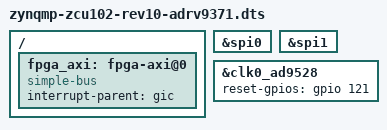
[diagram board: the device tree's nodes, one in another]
#include "zynqmp-zcu102-rev1.0.dts"

//&i2c1 {
//	i2cswitch@75 {
//		i2c@0 {
//			#address-cells = <1>;
//			#size-cells = <0>;
//			reg = <0>;
//			/* HPC0_IIC */
//			ad7291@2f {
//				compatible = "adi,ad7291";
//				reg = <0x2f>;
//			};
//
//			eeprom@50 {
//				compatible = "at24,24c02";
//				reg = <0x50>;
//			};
//
//		};
//	};
//};

/ {
	fpga_axi: fpga-axi@0 {
		interrupt-parent = <&gic>;
		compatible = "simple-bus";
		#address-cells = <0x2>;
		#size-cells = <0x1>;
		ranges = <0 0 0 0 0xffffffff>;

	};
};

&spi0 {
	status = "okay";
};

&spi1 {
	status = "okay";
};

#define fmc_spi spi0

#include "adi-adrv9371.dtsi"

// ad9371_dac_fifo_bypass_s 60
// ad9528_reset_b,       // 59
// ad9528_sysref_req,    // 58
// ad9371_tx1_enable,    // 57
// ad9371_tx2_enable,    // 56
// ad9371_rx1_enable,    // 55
// ad9371_rx2_enable,    // 54
// ad9371_test,          // 53
// ad9371_reset_b,       // 52
// ad9371_gpint,         // 51
// ad9371_gpio_00,       // 50
// ad9371_gpio_01,       // 49
// ad9371_gpio_02,       // 48
// ad9371_gpio_03,       // 47
// ad9371_gpio_04,       // 46
// ad9371_gpio_05,       // 45
// ad9371_gpio_06,       // 44
// ad9371_gpio_07,       // 43
// ad9371_gpio_15,       // 42
// ad9371_gpio_08,       // 41
// ad9371_gpio_09,       // 40
// ad9371_gpio_10,       // 39
// ad9371_gpio_11,       // 38
// ad9371_gpio_12,       // 37
// ad9371_gpio_14,       // 36
// ad9371_gpio_13,       // 35
// ad9371_gpio_17,       // 34
// ad9371_gpio_16,       // 33
// ad9371_gpio_18}));    // 32 + 78

//&trx0_ad9371 {
//	reset-gpios = <&gpio 130 0>;
//	test-gpios = <&gpio 131 0>;
//	sysref_req-gpios = <&gpio 136 0>;
//	rx2_enable-gpios = <&gpio 132 0>;
//	rx1_enable-gpios = <&gpio 133 0>;
//	tx2_enable-gpios = <&gpio 134 0>;
//	tx1_enable-gpios = <&gpio 135 0>;
//
//	adi,jesd204-deframer-eq-setting = <3>;
//};

&clk0_ad9528 {
	reset-gpios = <&gpio 121 0>;
};


#include "rau-fpga.dtsi"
